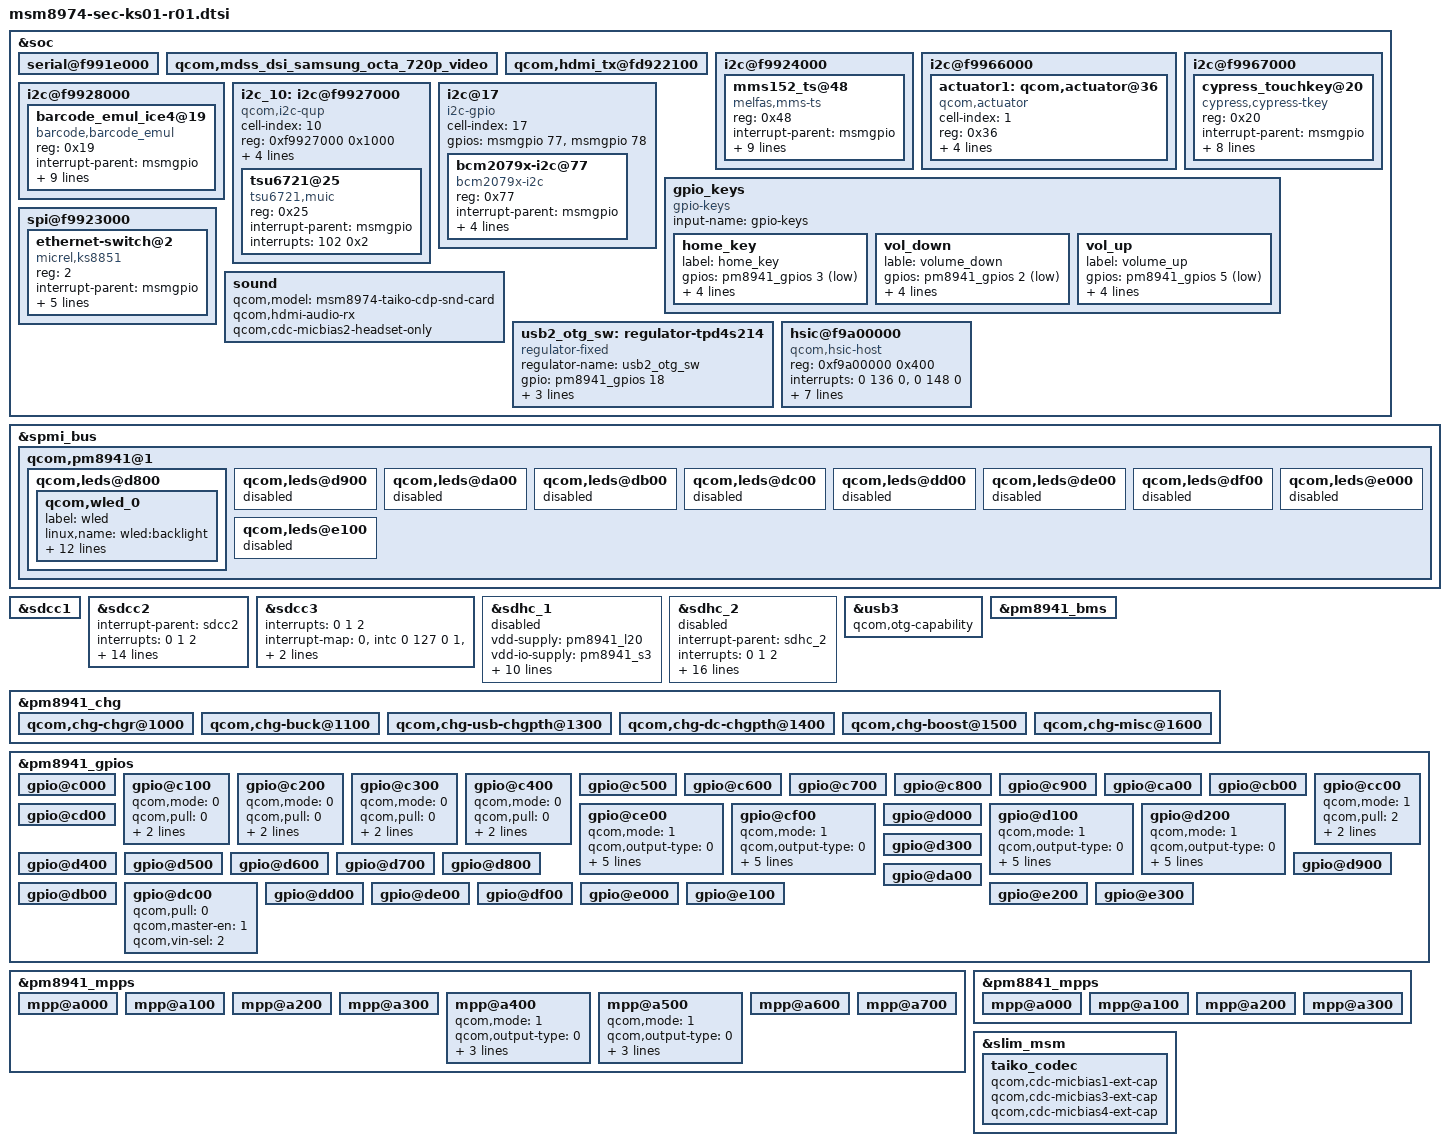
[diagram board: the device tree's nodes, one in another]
/* Copyright (c) 2012-2013, The Linux Foundation. All rights reserved.
 *
 * This program is free software; you can redistribute it and/or modify
 * it under the terms of the GNU General Public License version 2 and
 * only version 2 as published by the Free Software Foundation.
 *
 * This program is distributed in the hope that it will be useful,
 * but WITHOUT ANY WARRANTY; without even the implied warranty of
 * MERCHANTABILITY or FITNESS FOR A PARTICULAR PURPOSE.  See the
 * GNU General Public License for more details.
 */

/include/ "dsi_panel_magana_octa_720p_video.dtsi"
/include/ "msm8974-leds.dtsi"
/include/ "msm8974-camera-sensor-cdp-mtp.dtsi"
/include/ "msm8974-tdmb-ks01-r00.dtsi"

&soc {
	serial@f991e000 {
		status = "ok";
	};


	qcom,mdss_dsi_samsung_octa_720p_video {
		status = "ok";
	};


	qcom,hdmi_tx@fd922100 {
		status = "ok";
	};

	i2c@f9924000 {
		mms152_ts@48 {
			compatible = "melfas,mms-ts";
			reg = <0x48>;
			interrupt-parent = <&msmgpio>;
			interrupts = <80 0>;
			vdd_en-gpio = <&pm8941_gpios 9 0x1>;
			vcc_i2c-supply = <&pm8941_lvs1>;
			melfas,scl-gpio = <&msmgpio 7 0x00>;
			melfas,sda-gpio = <&msmgpio 6 0x00>;
			melfas,irq-gpio = <&msmgpio 80 0x00>;
			melfas,panel-coords = <0  0 720 1280>;
			melfas,config_fw_version = "melfas mms152";
			melfas,i2c-pull-up = <1>;
		};
	};

	i2c@f9966000 {
		actuator1: qcom,actuator@36 {
			compatible = "qcom,actuator";
		    	cell-index = <1>;			
			reg = <0x36>;
			gpios = <&msmgpio 55 0>,
					<&msmgpio 56 0>;
			qcom,gpio-req-tbl-num = <0 1>;
			qcom,gpio-req-tbl-flags = <1 1>;
			qcom,gpio-req-tbl-label = "I2C_DATA0",
								"I2C_CLK0";
		};
	};
	
	i2c@f9967000 {
		cypress_touchkey@20 {
			compatible = "cypress,cypress-tkey";
			reg = <0x20>;
			interrupt-parent = <&msmgpio>;
			interrupts = <79 0>;
			vdd_led-gpio = <&pm8941_gpios 27 0x1>;
			vcc_en-supply = <&pm8941_lvs3>;
			cypress,scl-gpio = <&msmgpio 84 0x00>;
			cypress,sda-gpio = <&msmgpio 83 0x00>;
			cypress,irq-gpio = <&msmgpio 79 0x00>;
			cypress,tkey-keycodes = <158 139>;
			cypress,i2c-pull-up = <1>;
		};
	};

	i2c@f9928000 {
		barcode_emul_ice4@19 {
			compatible = "barcode,barcode_emul";
			reg = <0x19>;			
			interrupt-parent = <&msmgpio>;
			interrupts = <64 0>;
			barcode,irda_en = <&pm8941_gpios 04 0x1>;
			barcode,cresetb = <&msmgpio 57 0x00>;
			barcode,reset_n = <&msmgpio 58 0x00>;
			barcode,cdone = <&msmgpio 53 0x00>;
			barcode,scl-gpio = <&msmgpio 30 0x00>;
			barcode,sda-gpio = <&msmgpio 29 0x00>;
			barcode,irq-gpio = <&msmgpio 64 0x00>;			
			barcode,i2c-pull-up = <1>;
		};
	};

	i2c_10: i2c@f9927000 {
		cell-index = <10>;
		compatible = "qcom,i2c-qup";
		reg = <0xf9927000 0x1000>;
		#address-cells = <1>;
		#size-cells = <0>;
		reg-names = "qup_phys_addr";
		interrupts = <0 99 0>;
		interrupt-names = "qup_err_intr";
		qcom,i2c-bus-freq = <100000>;
		qcom,i2c-src-freq = <50000000>;
		qcom,master-id = <86>;	
	};

	i2c@f9927000 {
		tsu6721@25 {
			compatible = "tsu6721,muic";
			reg = <0x25>;
			interrupt-parent = <&msmgpio>;
			interrupts = <102 0x2>;
		};
	};

	i2c@17{
		cell-index = <17>;
		compatible = "i2c-gpio";
		gpios = <&msmgpio 77 0
			 &msmgpio 78 0
			>;
		bcm2079x-i2c@77{
			compatible = "bcm2079x-i2c";
			reg = <0x77>;
			interrupt-parent = <&msmgpio>;
			interrupts = <59 0>;
			bcm2079x-i2c,irq-gpio = <&msmgpio 59 0x00>;
			bcm2079x-i2c,en-gpio = <&pm8941_gpios 13 0x1>;
			bcm2079x-i2c,wake-gpio = <&msmgpio 63 0x00>;
		};
	};

	gpio_keys {
		compatible = "gpio-keys";
		input-name = "gpio-keys";

		home_key {
			label = "home_key";
			gpios = <&pm8941_gpios 3 0x1>;
			linux,input-type = <1>;
			linux,code = <102>;
			gpio-key,wakeup;
			debounce-interval = <15>;
		};

		vol_down {
			lable = "volume_down";
			gpios = <&pm8941_gpios 2 0x1>;
			linux,input-type = <1>;
			linux,code = <114>;
			gpio-key,wakeup;
			debounce-interval = <15>;
		};
 
		vol_up {
			label = "volume_up";
			gpios = <&pm8941_gpios 5 0x1>;
			linux,input-type = <1>;
			linux,code = <115>;
			gpio-key,wakeup;
			debounce-interval = <15>;
		};
	};

	spi@f9923000 {
		ethernet-switch@2 {
			compatible = "micrel,ks8851";
			reg = <2>;
			interrupt-parent = <&msmgpio>;
			interrupts = <94 0>;
			spi-max-frequency = <4800000>;
			rst-gpio = <&pm8941_mpps 6 0>;
			vdd-io-supply = <&spi_eth_vreg>;
			vdd-phy-supply = <&spi_eth_vreg>;
		};
	};

	sound {
		qcom,model = "msm8974-taiko-cdp-snd-card";
		qcom,hdmi-audio-rx;
		qcom,cdc-micbias2-headset-only;
	};

	usb2_otg_sw: regulator-tpd4s214 {
		compatible = "regulator-fixed";
		regulator-name = "usb2_otg_sw";
		gpio = <&pm8941_gpios 18 0>;
		parent-supply = <&pm8941_boost>;
		startup-delay-us = <17000>;
		enable-active-high;
	};

	hsic@f9a00000 {
		compatible = "qcom,hsic-host";
		reg = <0xf9a00000 0x400>;
                interrupts = <0 136 0>, <0 148 0>;
                interrupt-names = "core_irq", "async_irq";
		HSIC_VDDCX-supply = <&pm8841_s2>;
		HSIC_GDSC-supply = <&gdsc_usb_hsic>;
		hsic,strobe-gpio = <&msmgpio 144 0x00>;
		hsic,data-gpio = <&msmgpio 145 0x00>;
		hsic,ignore-cal-pad-config;
		hsic,strobe-pad-offset = <0x2050>;
		hsic,data-pad-offset = <0x2054>;
	};

};

&spmi_bus {
	qcom,pm8941@1 {
		qcom,leds@d800 {
			status = "okay";
			qcom,wled_0 {
				label = "wled";
				linux,name = "wled:backlight";
				linux,default-trigger = "bkl-trigger";
				qcom,cs-out-en;
				qcom,op-fdbck;
				qcom,default-state = "on";
				qcom,max-current = <25>;
				qcom,ctrl-delay-us = <0>;
				qcom,boost-curr-lim = <3>;
				qcom,cp-sel = <0>;
				qcom,switch-freq = <2>;
				qcom,ovp-val = <2>;
				qcom,num-strings = <1>;
				qcom,id = <0>;
			};
		};

		qcom,leds@d900 {
			status = "disabled";
		};

		qcom,leds@da00 {
			status = "disabled";
		};

		qcom,leds@db00 {
			status = "disabled";
		};

		qcom,leds@dc00 {
			status = "disabled";
		};

		qcom,leds@dd00 {
			status = "disabled";
		};

		qcom,leds@de00 {
			status = "disabled";
		};

		qcom,leds@df00 {
			status = "disabled";
		};

		qcom,leds@e000 {
			status = "disabled";
		};

		qcom,leds@e100 {
			status = "disabled";
		};
	};
};

&sdcc1 {
       status = "ok";
};

&sdcc2 {
	#address-cells = <0>;
	interrupt-parent = <&sdcc2>;
	interrupts = <0 1 2>;
	#interrupt-cells = <1>;
	interrupt-map-mask = <0xffffffff>;
	interrupt-map = <0 &intc 0 125 0
			1 &intc 0 220 0
			2 &msmgpio 62 0x3>;
	interrupt-names = "core_irq", "bam_irq", "status_irq";

	vdd-supply = <&pm8941_l21>;
	vdd-io-supply = <&pm8941_l13>;
	qcom,vdd-voltage-level = <2950000 2950000>;
	qcom,vdd-current-level = <9000 800000>;
	qcom,vdd-io-voltage-level = <1800000 2950000>;
	qcom,vdd-io-current-level = <6 22000>;

	qcom,clk-rates = <400000 20000000 25000000 50000000 100000000 200000000>;
	qcom,sup-voltages = <2950 2950>;

	cd-gpios = <&msmgpio 62 0x1>;
	wp-gpios = <&pm8941_gpios 29 0x1>;
	status = "ok";
};

&sdcc3 {
	interrupts = <0 1 2>;
	interrupt-map = <0 &intc 0 127 0
		1 &intc 0 223 0
		2 &msmgpio 37 0x8>;
	interrupt-names = "core_irq", "bam_irq", "sdiowakeup_irq";
	qcom,sup-voltages = <1800 1800>;
	status = "ok";
};

&sdhc_1 {
	vdd-supply = <&pm8941_l20>;
	vdd-io-supply = <&pm8941_s3>;

	qcom,vdd-voltage-level = <2950000 2950000>;
	qcom,vdd-current-level = <800 500000>;

	qcom,vdd-io-always-on;
	qcom,vdd-io-voltage-level = <1800000 1800000>;
	qcom,vdd-io-current-level = <250 154000>;

	qcom,pad-pull-on = <0x0 0x3 0x3>; /* no-pull, pull-up, pull-up */
	qcom,pad-pull-off = <0x0 0x3 0x3>; /* no-pull, pull-up, pull-up */
	qcom,pad-drv-on = <0x7 0x4 0x4>; /* 16mA, 10mA, 10mA */
	qcom,pad-drv-off = <0x0 0x0 0x0>; /* 2mA, 2mA, 2mA */

	qcom,nonremovable;
	status = "disable";
};

&sdhc_2 {
	#address-cells = <0>;
	interrupt-parent = <&sdhc_2>;
	interrupts = <0 1 2>;
	#interrupt-cells = <1>;
	interrupt-map-mask = <0xffffffff>;
	interrupt-map = <0 &intc 0 125 0
			1 &intc 0 221 0
			2 &msmgpio 62 0x3>;
	interrupt-names = "hc_irq", "pwr_irq", "status_irq";
	cd-gpios = <&msmgpio 62 0x1>;

	vdd-supply = <&pm8941_l21>;
	vdd-io-supply = <&pm8941_l13>;

	qcom,vdd-voltage-level = <2950000 2950000>;
	qcom,vdd-current-level = <9000 800000>;

	qcom,vdd-io-always-on;
	qcom,vdd-io-lpm-sup;
	qcom,vdd-io-voltage-level = <1800000 2950000>;
	qcom,vdd-io-current-level = <6 22000>;

	qcom,pad-pull-on = <0x0 0x3 0x3>; /* no-pull, pull-up, pull-up */
	qcom,pad-pull-off = <0x0 0x3 0x3>; /* no-pull, pull-up, pull-up */
	qcom,pad-drv-on = <0x7 0x4 0x4>; /* 16mA, 10mA, 10mA */
	qcom,pad-drv-off = <0x0 0x0 0x0>; /* 2mA, 2mA, 2mA */
	status = "disable";
};

&usb3 {
	qcom,otg-capability;
};

&pm8941_bms {
	status = "ok";
};

&pm8941_chg {
	status = "ok";

	qcom,chg-chgr@1000 {
		status = "ok";
	};

	qcom,chg-buck@1100 {
		status = "ok";
	};

	qcom,chg-usb-chgpth@1300 {
		status = "ok";
	};

	qcom,chg-dc-chgpth@1400 {
		status = "ok";
	};

	qcom,chg-boost@1500 {
		status = "ok";
	};

	qcom,chg-misc@1600 {
		status = "ok";
	};
};

&pm8941_gpios {
	gpio@c000 { /* GPIO 1 */
	};

	gpio@c100 { /* GPIO 2 */
		qcom,mode = <0>;
		qcom,pull = <0>;
		qcom,vin-sel = <2>;
		qcom,select = <0>;
	};

	gpio@c200 { /* GPIO 3 */
		qcom,mode = <0>;
		qcom,pull = <0>;
		qcom,vin-sel = <2>;
		qcom,src-sel = <0>;
	};

	gpio@c300 { /* GPIO 4 */
		qcom,mode = <0>;
		qcom,pull = <0>;
		qcom,vin-sel = <2>;
		qcom,src-sel = <0>;
	};

	gpio@c400 { /* GPIO 5 */
		qcom,mode = <0>;
		qcom,pull = <0>;
		qcom,vin-sel = <2>;
		qcom,src-sel = <0>;
	};

	gpio@c500 { /* GPIO 6 */
	};

	gpio@c600 { /* GPIO 7 */
	};

	gpio@c700 { /* GPIO 8 */
	};

	gpio@c800 { /* GPIO 9 */
	};

	gpio@c900 { /* GPIO 10 */
	};

	gpio@ca00 { /* GPIO 11 */
	};

	gpio@cb00 { /* GPIO 12 */
	};

	gpio@cc00 { /* GPIO 13 */
		qcom,mode = <1>;
		qcom,pull = <2>;
		qcom,vin-sel = <2>;
		qcom,src-sel = <0>;
	};

	gpio@cd00 { /* GPIO 14 */
	};

	gpio@ce00 { /* GPIO 15 */
		qcom,mode = <1>;
		qcom,output-type = <0>;
		qcom,pull = <5>;
		qcom,vin-sel = <2>;
		qcom,out-strength = <1>;
		qcom,src-sel = <2>;
		qcom,master-en = <1>;
	};

	gpio@cf00 { /* GPIO 16 */
		qcom,mode = <1>;
		qcom,output-type = <0>;
		qcom,pull = <2>;
		qcom,vin-sel = <2>;
		qcom,out-strength = <2>;
		qcom,src-sel = <2>;
		qcom,master-en = <1>;
	};

	gpio@d000 { /* GPIO 17 */
	};

	gpio@d100 { /* GPIO 18 */
		/* usb2_otg_sw regulator enable */
		qcom,mode = <1>;		/* Digital output */
		qcom,output-type = <0>;		/* CMOS logic */
		qcom,invert = <0>; 		/* Output low initially */
		qcom,vin-sel = <2>; 		/* PM8941 S3 = 1.8 V */
		qcom,src-sel = <0>; 		/* Constant */
		qcom,out-strength = <2>;	/* Medium drive strength */
		qcom,master-en = <1>;		/* Enable GPIO */
	};

	gpio@d200 { /* GPIO 19 */
		qcom,mode = <1>;		/* QPNP_PIN_MODE_DIG_OUT */
		qcom,output-type = <0>;		/* QPNP_PIN_OUT_BUF_CMOS */
		qcom,pull = <5>;		/* QPNP_PIN_PULL_NO */
		qcom,vin-sel = <2>;		/* QPNP_PIN_VIN2 */
		qcom,out-strength = <2>;	/* QPNP_PIN_OUT_STRENGTH_MED */
		qcom,src-sel = <0>;		/* QPNP_PIN_SEL_FUNC_CONSTANT */
		qcom,master-en = <1>;
	};

	gpio@d300 { /* GPIO 20 */
	};

	gpio@d400 { /* GPIO 21 */
	};

	gpio@d500 { /* GPIO 22 */
	};

	gpio@d600 { /* GPIO 23 */
	};

	gpio@d700 { /* GPIO 24 */
	};

	gpio@d800 { /* GPIO 25 */
	};

	gpio@d900 { /* GPIO 26 */
	};

	gpio@da00 { /* GPIO 27 */
	};

	gpio@db00 { /* GPIO 28 */
	};

	gpio@dc00 { /* GPIO 29 */
		qcom,pull = <0>; /* set to default pull */
		qcom,master-en = <1>;
		qcom,vin-sel = <2>; /* select 1.8 V source */
	};

	gpio@dd00 { /* GPIO 30 */
	};

	gpio@de00 { /* GPIO 31 */
	};

	gpio@df00 { /* GPIO 32 */
	};

	gpio@e000 { /* GPIO 33 */
	};

	gpio@e100 { /* GPIO 34 */
	};

	gpio@e200 { /* GPIO 35 */
	};

	gpio@e300 { /* GPIO 36 */
	};
};

&pm8941_mpps {

	mpp@a000 { /* MPP 1 */
	};

	mpp@a100 { /* MPP 2 */
	};

	mpp@a200 { /* MPP 3 */
	};

	mpp@a300 { /* MPP 4 */
	};

	mpp@a400 { /* MPP 5 */
		/* SPI_ETH config */
		qcom,mode = <1>; /* DIG_OUT */
		qcom,output-type = <0>; /* CMOS */
		qcom,vin-sel = <2>; /* PM8941_S3 1.8V > 1.6V */
		qcom,src-sel = <0>; /* CONSTANT */
		qcom,master-en = <1>; /* ENABLE MPP */
	};

	mpp@a500 { /* MPP 6 */
		/* SPI_ETH_RST config */
		qcom,mode = <1>; /* DIG_OUT */
		qcom,output-type = <0>; /* CMOS */
		qcom,vin-sel = <2>; /* PM8941_S3 1.8V > 1.6V */
		qcom,src-sel = <0>; /* CONSTANT */
		qcom,master-en = <1>; /* ENABLE MPP */
	};

	mpp@a600 { /* MPP 7 */
	};

	mpp@a700 { /* MPP 8 */
	};
};

&pm8841_mpps {

	mpp@a000 { /* MPP 1 */
	};

	mpp@a100 { /* MPP 2 */
	};

	mpp@a200 { /* MPP 3 */
	};

	mpp@a300 { /* MPP 4 */
	};
};

&slim_msm {
	taiko_codec {
		qcom,cdc-micbias1-ext-cap;
		qcom,cdc-micbias3-ext-cap;
		qcom,cdc-micbias4-ext-cap;
	};
};
